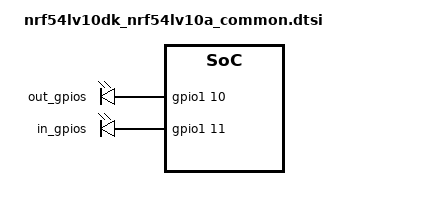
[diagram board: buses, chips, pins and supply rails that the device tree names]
/*
 * Copyright (c) 2025 Nordic Semiconductor ASA
 *
 * SPDX-License-Identifier: LicenseRef-Nordic-5-Clause
 */

/ {
	/* Test requirements:
	 * out-gpios[0] wire connected with in-gpios[0],
	 * out-gpios[1] wire connected with in-gpios[1],
	 * etc.
	 * Output-input GPIO pair must have identical active level flag.
	 */
	test_gpios {
		compatible = "gpio-leds";

		out_gpios: out_gpios {
			gpios = <&gpio1 10 GPIO_ACTIVE_HIGH>;
		};

		in_gpios: in_gpios {
			gpios = <&gpio1 11 GPIO_ACTIVE_HIGH>;
		};
	};
};

&gpiote20 {
	status = "okay";
};

&gpio1 {
	status = "okay";
};
